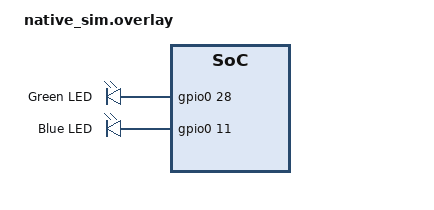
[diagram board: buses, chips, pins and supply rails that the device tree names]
/ {

	aliases {
		led0 = &led0;
		led1 = &led1;
	};

    /* Add an extra LED to the existing 'leds' node */
	leds {
		compatible = "gpio-leds";
		led0: led_0 {
			gpios = <&gpio0 28 GPIO_ACTIVE_HIGH>;
			label = "Green LED";
		};
		led1: led_1 {
			gpios = <&gpio0 11 GPIO_ACTIVE_HIGH>;
			label = "Blue LED";
		};
	};

};

